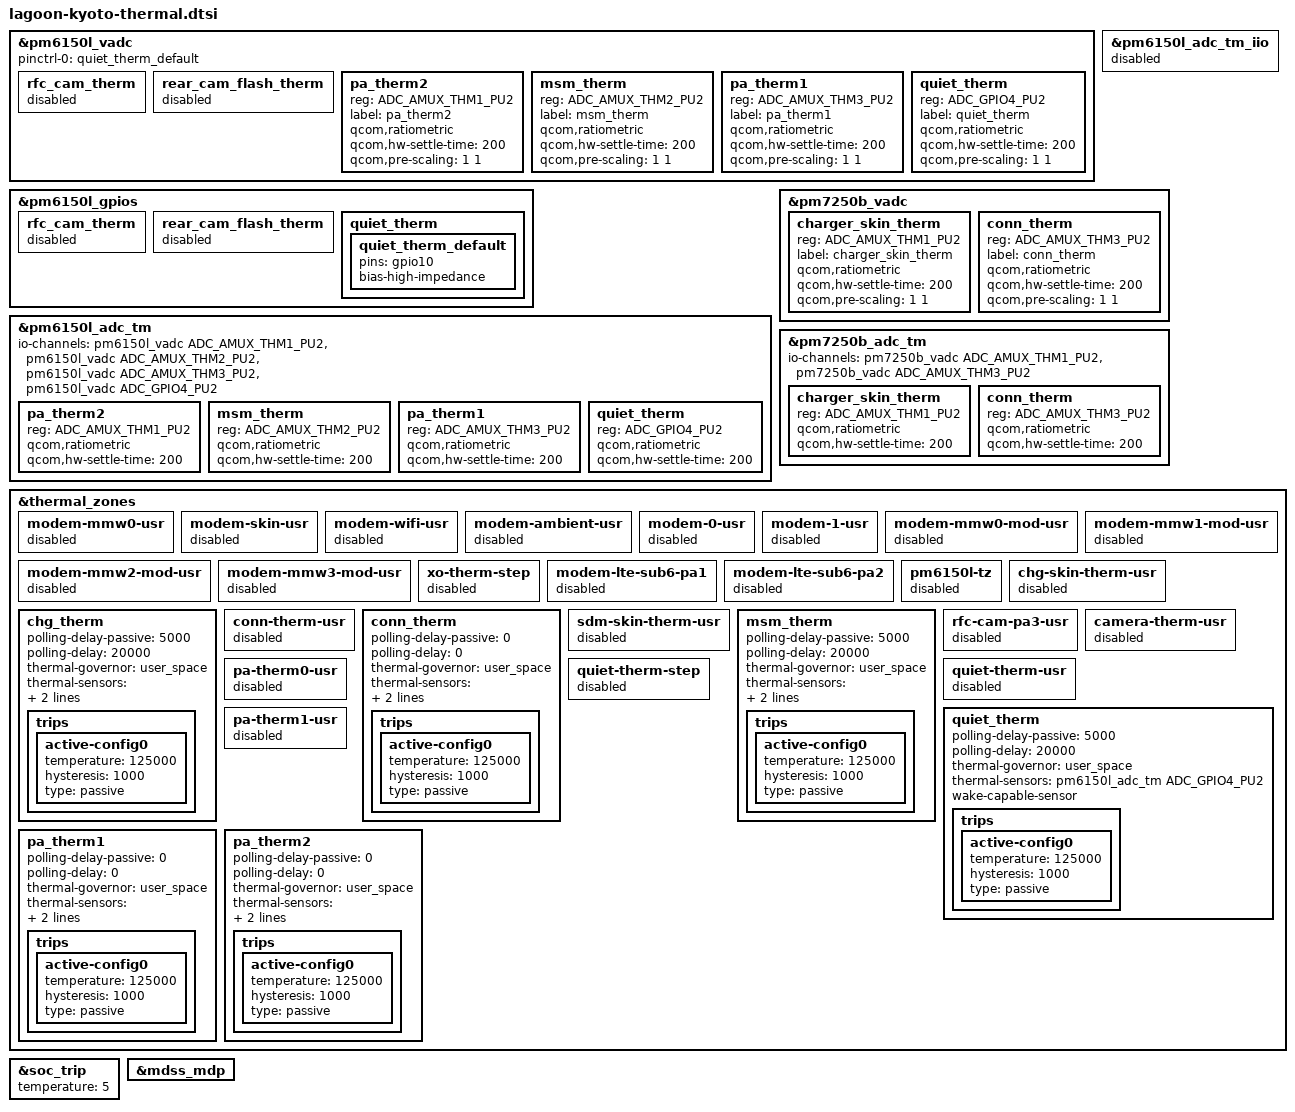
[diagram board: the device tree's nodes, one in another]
#include "moto_therm_sys_temp.dtsi"

&pm6150l_vadc {
	pinctrl-0 = <&quiet_therm_default>;

	rfc_cam_therm {
		status = "disabled";
	};

	rear_cam_flash_therm {
		status = "disabled";
	};

	pa_therm2 {
		reg = <ADC_AMUX_THM1_PU2>;
		label = "pa_therm2";
		qcom,ratiometric;
		qcom,hw-settle-time = <200>;
		qcom,pre-scaling = <1 1>;
	};

	msm_therm {
		reg = <ADC_AMUX_THM2_PU2>;
		label = "msm_therm";
		qcom,ratiometric;
		qcom,hw-settle-time = <200>;
		qcom,pre-scaling = <1 1>;
	};

	pa_therm1 {
		reg = <ADC_AMUX_THM3_PU2>;
		label = "pa_therm1";
		qcom,ratiometric;
		qcom,hw-settle-time = <200>;
		qcom,pre-scaling = <1 1>;
	};

	quiet_therm {
		reg = <ADC_GPIO4_PU2>; //gpio10
		label = "quiet_therm";
		qcom,ratiometric;
		qcom,hw-settle-time = <200>;
		qcom,pre-scaling = <1 1>;
	};
};

&pm6150l_gpios {
	rfc_cam_therm {
		status = "disabled";
	};

	rear_cam_flash_therm {
		status = "disabled";
	};

	quiet_therm {
		quiet_therm_default: quiet_therm_default {
			pins = "gpio10";
			bias-high-impedance;
		};
	};
};

&pm6150l_adc_tm {
	#address-cells = <1>;
	#size-cells = <0>;
	io-channels = <&pm6150l_vadc ADC_AMUX_THM1_PU2>,
			<&pm6150l_vadc ADC_AMUX_THM2_PU2>,
			<&pm6150l_vadc ADC_AMUX_THM3_PU2>,
			<&pm6150l_vadc ADC_GPIO4_PU2>;

	pa_therm2 {
		reg = <ADC_AMUX_THM1_PU2>;
		qcom,ratiometric;
		qcom,hw-settle-time = <200>;
	};

	msm_therm {
		reg = <ADC_AMUX_THM2_PU2>;
		qcom,ratiometric;
		qcom,hw-settle-time = <200>;
	};

	pa_therm1 {
		reg = <ADC_AMUX_THM3_PU2>;
		qcom,ratiometric;
		qcom,hw-settle-time = <200>;
	};

	quiet_therm {
		reg = <ADC_GPIO4_PU2>;
		qcom,ratiometric;
		qcom,hw-settle-time = <200>;
	};
};

&pm6150l_adc_tm_iio {
	status = "disabled";
};

&pm7250b_vadc {
	#address-cells = <1>;
	#size-cells = <0>;

	charger_skin_therm {
		reg = <ADC_AMUX_THM1_PU2>;
		label = "charger_skin_therm";
		qcom,ratiometric;
		qcom,hw-settle-time = <200>;
		qcom,pre-scaling = <1 1>;
	};

	conn_therm {
		reg = <ADC_AMUX_THM3_PU2>;
		label = "conn_therm";
		qcom,ratiometric;
		qcom,hw-settle-time = <200>;
		qcom,pre-scaling = <1 1>;
	};
};

&pm7250b_adc_tm {
	#address-cells = <1>;
	#size-cells = <0>;
	io-channels = <&pm7250b_vadc ADC_AMUX_THM1_PU2>,
			<&pm7250b_vadc ADC_AMUX_THM3_PU2>;

	/* Channel nodes */
	charger_skin_therm {
		reg = <ADC_AMUX_THM1_PU2>;
		qcom,ratiometric;
		qcom,hw-settle-time = <200>;
	};

	conn_therm {
		reg = <ADC_AMUX_THM3_PU2>;
		qcom,ratiometric;
		qcom,hw-settle-time = <200>;
	};
};

&thermal_zones {
	/* Don't support sensors in 80-pj360-35_d */
	modem-mmw0-usr {
		status = "disabled";
	};
	modem-skin-usr {
		status = "disabled";
	};
	modem-wifi-usr {
		status = "disabled";
	};
	modem-ambient-usr {
		status = "disabled";
	};
	modem-0-usr {
		status = "disabled";
	};
	modem-1-usr {
		status = "disabled";
	};
	modem-mmw0-mod-usr {
		status = "disabled";
	};
	modem-mmw1-mod-usr {
		status = "disabled";
	};
	modem-mmw2-mod-usr {
		status = "disabled";
	};
	modem-mmw3-mod-usr {
		status = "disabled";
	};

	xo-therm-step {
		status = "disabled";
	};

	/* equal to pa_therm1 */
	modem-lte-sub6-pa1 {
		status = "disabled";
	};
	/* equal to pa_therm2 */
	modem-lte-sub6-pa2 {
		status = "disabled";
	};
	pm6150l-tz {
		status = "disabled";
	};

	chg-skin-therm-usr {
		status = "disabled";
	};
	chg_therm {
		polling-delay-passive = <5000>;
		polling-delay = <20000>;
		thermal-governor = "user_space";
		thermal-sensors = <&pm7250b_adc_tm ADC_AMUX_THM1_PU2>;
		wake-capable-sensor;
		trips {
			active-config0 {
				temperature = <125000>;
				hysteresis = <1000>;
				type = "passive";
			};
		};
	};

	conn-therm-usr {
		status = "disabled";
	};
	conn_therm {
		polling-delay-passive = <0>;
		polling-delay = <0>;
		thermal-governor = "user_space";
		thermal-sensors = <&pm7250b_adc_tm ADC_AMUX_THM3_PU2>;
		wake-capable-sensor;
		trips {
			active-config0 {
				temperature = <125000>;
				hysteresis = <1000>;
				type = "passive";
			};
		};
	};

	sdm-skin-therm-usr {
		status = "disabled";
	};
	msm_therm {
		polling-delay-passive = <5000>;
		polling-delay = <20000>;
		thermal-governor = "user_space";
		thermal-sensors = <&pm6150l_adc_tm ADC_AMUX_THM2_PU2>;
		wake-capable-sensor;
		trips {
			active-config0 {
				temperature = <125000>;
				hysteresis = <1000>;
				type = "passive";
			};
		};
	};

	rfc-cam-pa3-usr {
		status = "disabled";
	};

	camera-therm-usr {
		status = "disabled";
	};

	quiet-therm-step {
		status = "disabled";
	};
	quiet-therm-usr {
		status = "disabled";
	};
	quiet_therm {
		polling-delay-passive = <5000>;
		polling-delay = <20000>;
		thermal-governor = "user_space";
		thermal-sensors = <&pm6150l_adc_tm ADC_GPIO4_PU2>;
		wake-capable-sensor;
		trips {
			active-config0 {
				temperature = <125000>;
				hysteresis = <1000>;
				type = "passive";
			};
		};
	};

	pa-therm0-usr {
		status = "disabled";
	};
	pa_therm1 {
		polling-delay-passive = <0>;
		polling-delay = <0>;
		thermal-governor = "user_space";
		thermal-sensors = <&pm6150l_adc_tm ADC_AMUX_THM3_PU2>;
		wake-capable-sensor;
		trips {
			active-config0 {
				temperature = <125000>;
				hysteresis = <1000>;
				type = "passive";
			};
		};
	};

	pa-therm1-usr {
		status = "disabled";
	};
	pa_therm2 {
		polling-delay-passive = <0>;
		polling-delay = <0>;
		thermal-governor = "user_space";
		thermal-sensors = <&pm6150l_adc_tm ADC_AMUX_THM1_PU2>;
		wake-capable-sensor;
		trips {
			active-config0 {
				temperature = <125000>;
				hysteresis = <1000>;
				type = "passive";
			};
		};
	};
};

&soc_trip {
	temperature = <5>;
};

&mdss_mdp {
    /delete-property/ #cooling-cells;
};
